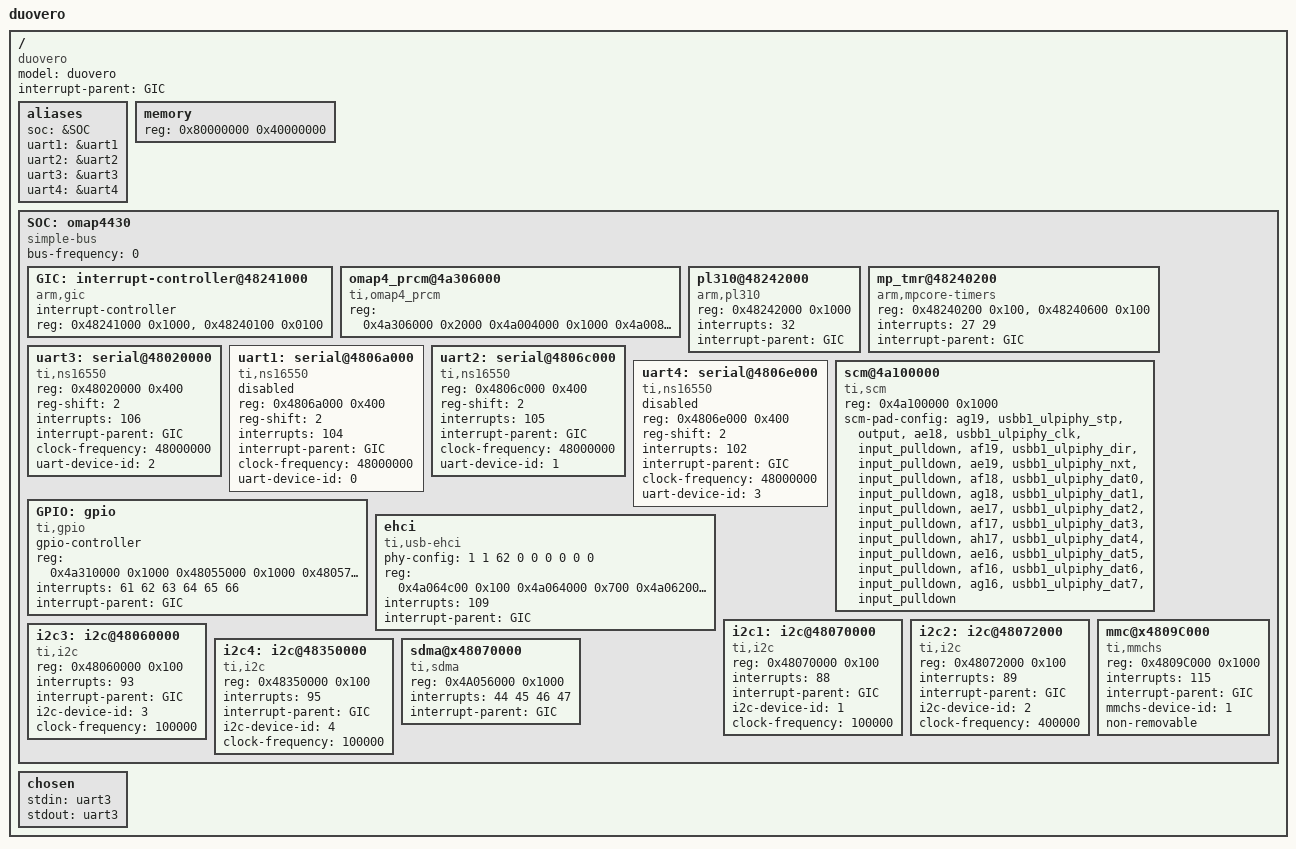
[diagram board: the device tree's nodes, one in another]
/*-
 * Copyright (c) 2011 The FreeBSD Foundation
 * All rights reserved.
 *
 * Developed by Damjan Marion <damjan.marion@gmail.com>
 *
 * Redistribution and use in source and binary forms, with or without
 * modification, are permitted provided that the following conditions
 * are met:
 * 1. Redistributions of source code must retain the above copyright
 *    notice, this list of conditions and the following disclaimer.
 * 2. Redistributions in binary form must reproduce the above copyright
 *    notice, this list of conditions and the following disclaimer in the
 *    documentation and/or other materials provided with the distribution.
 *
 * THIS SOFTWARE IS PROVIDED BY THE AUTHOR AND CONTRIBUTORS ``AS IS'' AND
 * ANY EXPRESS OR IMPLIED WARRANTIES, INCLUDING, BUT NOT LIMITED TO, THE
 * IMPLIED WARRANTIES OF MERCHANTABILITY AND FITNESS FOR A PARTICULAR PURPOSE
 * ARE DISCLAIMED. IN NO EVENT SHALL THE AUTHOR OR CONTRIBUTORS BE LIABLE
 * FOR ANY DIRECT, INDIRECT, INCIDENTAL, SPECIAL, EXEMPLARY, OR CONSEQUENTIAL
 * DAMAGES (INCLUDING, BUT NOT LIMITED TO, PROCUREMENT OF SUBSTITUTE GOODS
 * OR SERVICES; LOSS OF USE, DATA, OR PROFITS; OR BUSINESS INTERRUPTION)
 * HOWEVER CAUSED AND ON ANY THEORY OF LIABILITY, WHETHER IN CONTRACT, STRICT
 * LIABILITY, OR TORT (INCLUDING NEGLIGENCE OR OTHERWISE) ARISING IN ANY WAY
 * OUT OF THE USE OF THIS SOFTWARE, EVEN IF ADVISED OF THE POSSIBILITY OF
 * SUCH DAMAGE.
 * 
 * $FreeBSD$
 */

/dts-v1/;

/ {
	model = "duovero";
	compatible = "duovero", "ti,omap4430";
	#address-cells = <1>;
	#size-cells = <1>;

	interrupt-parent = <&GIC>;

	aliases {
		soc = &SOC;
		uart1 = &uart1;
		uart2 = &uart2;
		uart3 = &uart3;
		uart4 = &uart4;
	};

	memory {
		device_type = "memory";
		reg = < 0x80000000 0x40000000 >;	/* 1GB RAM at 0x0 */
	};

	SOC: omap4430 {
		#address-cells = <1>;
		#size-cells = <1>;
		compatible = "simple-bus";
		ranges;
		bus-frequency = <0>;

		GIC: interrupt-controller@48241000 {
			compatible = "arm,gic";
			interrupt-controller;
			#address-cells = <0>;
			#interrupt-cells = <1>;
			reg =	< 0x48241000 0x1000 >,	/* Distributor Registers */
				< 0x48240100 0x0100 >;	/* CPU Interface Registers */
		};

		omap4_prcm@4a306000 {
	   		compatible = "ti,omap4_prcm";
   			reg =<  0x4a306000 0x2000
			    0x4a004000 0x1000
			    0x4a008000 0x8000>;
		};
				     
		pl310@48242000 {
			compatible = "arm,pl310";
			reg = < 0x48242000 0x1000 >;
			interrupts = < 32 >;
			interrupt-parent = < &GIC >;
		};

		mp_tmr@48240200 {
			compatible = "arm,mpcore-timers";
			#address-cells = <1>;
			#size-cells = <0>;
			reg =	< 0x48240200 0x100 >, /* Global Timer Registers */
				< 0x48240600 0x100 >; /* Private Timer Registers */
			interrupts = < 27 29 >;
			interrupt-parent = < &GIC >;
		};

		/*
		 * References for uart values
		 * reg: table 23-165
		 * interrupts: table 17-2, MA_IRQ_XX + 32, why 32?
		 * clock-frequency: section 23.3.1.1
		 */

		uart3: serial@48020000 {
			compatible = "ti,ns16550";
			reg = <0x48020000 0x400>;
			reg-shift = <2>;
			interrupts = < 106 >;
			interrupt-parent = <&GIC>;
			clock-frequency = <48000000>;
			uart-device-id = <2>;
		};

		uart1: serial@4806a000 {
			compatible = "ti,ns16550";
			reg = <0x4806a000 0x400>;
			reg-shift = <2>;
			interrupts = < 104 >;
			interrupt-parent = <&GIC>;
			clock-frequency = <48000000>;
			uart-device-id = <0>;
			status = "disabled";
		};

		uart2: serial@4806c000 {
			compatible = "ti,ns16550";
			reg = <0x4806c000 0x400>;
			reg-shift = <2>;
			interrupts = < 105 >;
			interrupt-parent = <&GIC>;
			clock-frequency = <48000000>;
			uart-device-id = <1>;
		};
		
		uart4: serial@4806e000 {
			compatible = "ti,ns16550";
			reg = <0x4806e000 0x400>;
			reg-shift = <2>;
			interrupts = < 102 >;
			interrupt-parent = <&GIC>;
			clock-frequency = <48000000>;
			uart-device-id = <3>;
			status = "disabled";
		};

		scm@4a100000 {
			compatible = "ti,scm";
			reg =	< 0x4a100000 0x1000 >;
			/* Set of triplets < padname, muxname, padstate> */
			scm-pad-config = 
				"ag19", "usbb1_ulpiphy_stp", "output",
				"ae18", "usbb1_ulpiphy_clk", "input_pulldown",
				"af19", "usbb1_ulpiphy_dir", "input_pulldown",
				"ae19", "usbb1_ulpiphy_nxt", "input_pulldown",
				"af18", "usbb1_ulpiphy_dat0", "input_pulldown",
				"ag18", "usbb1_ulpiphy_dat1", "input_pulldown",
				"ae17", "usbb1_ulpiphy_dat2", "input_pulldown",
				"af17", "usbb1_ulpiphy_dat3", "input_pulldown",
				"ah17", "usbb1_ulpiphy_dat4", "input_pulldown",
				"ae16", "usbb1_ulpiphy_dat5", "input_pulldown",
				"af16", "usbb1_ulpiphy_dat6", "input_pulldown",
				"ag16", "usbb1_ulpiphy_dat7", "input_pulldown";
		};

		GPIO: gpio {
			#gpio-cells = <3>;
			compatible = "ti,gpio";
			gpio-controller;
			reg =<	0x4a310000 0x1000
				0x48055000 0x1000
				0x48057000 0x1000
				0x48059000 0x1000
				0x4805b000 0x1000
				0x4805d000 0x1000>;
			interrupts = <61 62 63 64 65 66>;
			interrupt-parent = <&GIC>;
		};

		ehci {
			compatible = "ti,usb-ehci", "usb-ehci";
			/* 
			 * USB port PHY configuration is a tuple: <mode, reset, gpio_pin>
			 * mode is one of the following values:
			 *   0 - unknown
			 *   1 - PHY
			 *   2 - TLL
			 *   3 - HSIC
			 *
			 * reset indicates (if non-zero) if port reset is required 
			 * gpio_pin - GPIO pin that is used to perform reset
			 */
			phy-config = <  1 1 62
					0 0 0
					0 0 0>;
			reg = < 0x4a064c00 0x100	/* EHCI regs */
				0x4a064000 0x700	/* UHH regs */
				0x4a062000 0x1000>;	/* TLL regs */
			interrupts = <109>;
			interrupt-parent = <&GIC>;
		};

		/*
		 * References for i2c values
		 * reg: table 23-30
		 * interrupts: table 17-2, MA_IRQ_XX + 32
                 * Only i2c2 and i2c3 are brought out on the Duovero COM
		 * Only i2c2 is available on the Parlor expansion
		 * Both are available on the Chateau expansion
		 */

		i2c1: i2c@48070000 {
			compatible = "ti,i2c";
			reg = <	0x48070000 0x100 >;
			interrupts = <88>;
			interrupt-parent = <&GIC>;
			i2c-device-id = <1>;
			clock-frequency = <100000>;
		};

		i2c2: i2c@48072000 {
			compatible = "ti,i2c";
			reg = <	0x48072000 0x100 >;
			interrupts = <89>;
			interrupt-parent = <&GIC>;
			i2c-device-id = <2>;
			clock-frequency = <400000>;
		};

		i2c3: i2c@48060000 {
			compatible = "ti,i2c";
			reg = <	0x48060000 0x100 >;
			interrupts = <93>;
			interrupt-parent = <&GIC>;
			i2c-device-id = <3>;
			clock-frequency = <100000>;
		};

		i2c4: i2c@48350000 {
			compatible = "ti,i2c";
			reg = <	0x48350000 0x100 >;
			interrupts = <95>;
			interrupt-parent = <&GIC>;
			i2c-device-id = <4>;
			clock-frequency = <100000>;
		};

		sdma@x48070000 {
			compatible = "ti,sdma";
			reg = <	0x4A056000 0x1000 >;
			interrupts = <44 45 46 47>;
			interrupt-parent = <&GIC>;
		};

		mmc@x4809C000 {
			compatible = "ti,mmchs";
			reg = <0x4809C000 0x1000 >;
			interrupts = <115>;
			interrupt-parent = <&GIC>;
			mmchs-device-id = <1>;
			non-removable;
		};
	};

	chosen {
		stdin = "uart3";
		stdout = "uart3";
	};
};
